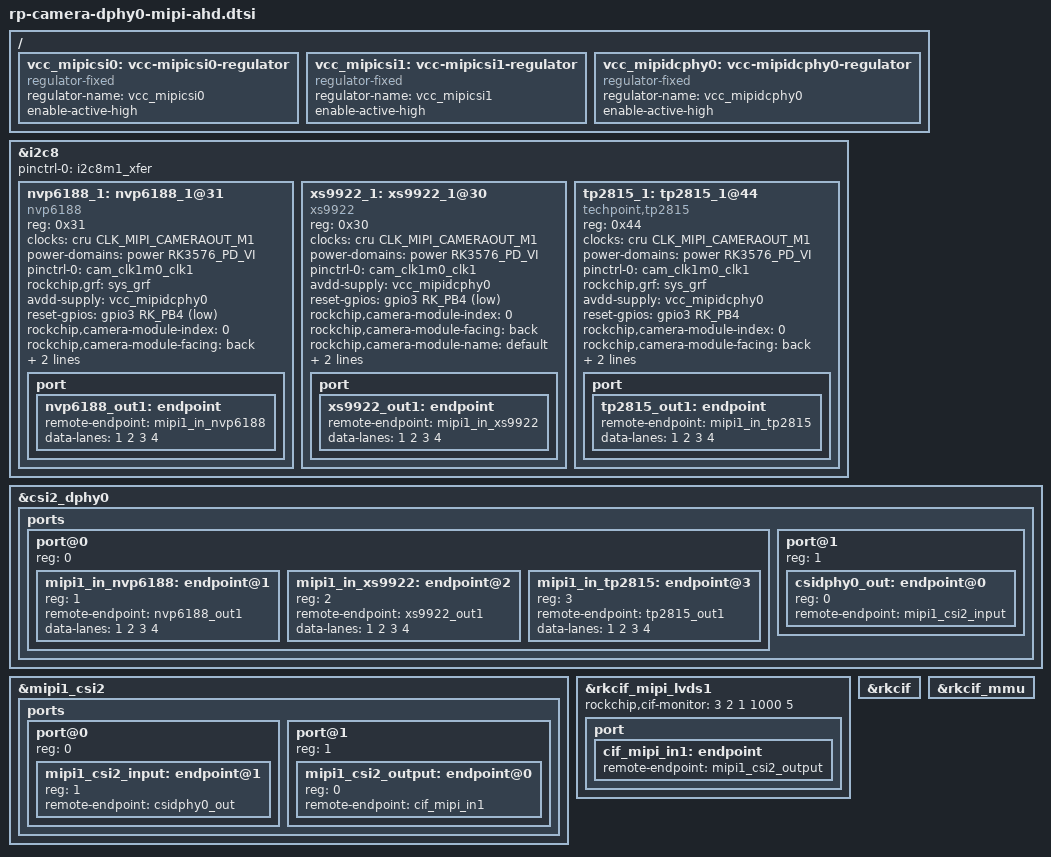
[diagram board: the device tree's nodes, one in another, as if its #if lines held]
/*
 * xs9922_0 -> MIPI_DPHY0 -> mipi_dcphy0 -> mipi0_csi2 -> cif0
 */

/{
    vcc_mipicsi0: vcc-mipicsi0-regulator {
        compatible = "regulator-fixed";
        regulator-name = "vcc_mipicsi0";
        enable-active-high;
    };

    vcc_mipicsi1: vcc-mipicsi1-regulator {
        compatible = "regulator-fixed";
        regulator-name = "vcc_mipicsi1";
        enable-active-high;
    };

    vcc_mipidcphy0: vcc-mipidcphy0-regulator {
        compatible = "regulator-fixed";
        regulator-name = "vcc_mipidcphy0";
        enable-active-high;
    };
};


&i2c8 {
    status = "okay";
    pinctrl-names = "default";
    pinctrl-0 = <&i2c8m1_xfer>;

    nvp6188_1: nvp6188_1@31 {
        reg = <0x31>;
        compatible = "nvp6188";
        status = "okay";
        clocks = <&cru CLK_MIPI_CAMERAOUT_M1>;
        clock-names = "xvclk";
        power-domains = <&power RK3576_PD_VI>;
        pinctrl-names = "default";
        pinctrl-0 = <&cam_clk1m0_clk1>;
		rockchip,grf = <&sys_grf>;
		avdd-supply = <&vcc_mipidcphy0>;
		
#if defined RP_RK3576S || defined PRO_RK3576X
        reset-gpios = <&gpio3 RK_PB4 GPIO_ACTIVE_LOW>;
        //power-gpios = <&nca9555_gpio IO_01 GPIO_ACTIVE_HIGH>;
#elif defined  DR4_RK3576X
        reset-gpios = <&gpio3 RK_PB4 GPIO_ACTIVE_LOW>;
        //power-gpios = <&nca9555_gpio IO_01 GPIO_ACTIVE_HIGH>;
#elif defined  PRO_RK3576_MID
        reset-gpios = <&gpio2 RK_PB0 GPIO_ACTIVE_LOW>;
        //power-gpios = <&nca9555_gpio IO_01 GPIO_ACTIVE_HIGH>;
#elif defined  PRO_BOX_RK3576
        reset-gpios = <&gpio0 RK_PA2 GPIO_ACTIVE_LOW>;
        //power-gpios = <&nca9555_gpio IO_01 GPIO_ACTIVE_HIGH>;
#else  //rk3576
        reset-gpios = <&nca9555_gpio IO_02 GPIO_ACTIVE_LOW>;
        //power-gpios = <&nca9555_gpio IO_03 GPIO_ACTIVE_HIGH>;
#endif        

        //avdd-supply = <&vcc_avdd>;
        //dovdd-supply = <&vcc_dovdd>;
        //dvdd-supply = <&vcc_dvdd>;
        rockchip,camera-module-index = <0>;
        rockchip,camera-module-facing = "back";
        rockchip,camera-module-name = "nvp6188";
        rockchip,camera-module-lens-name = "nvp6188";
        port {
            nvp6188_out1: endpoint {
                remote-endpoint = <&mipi1_in_nvp6188>;
                data-lanes = <1 2 3 4>;
            };
        };
    };
    
#ifdef PRO_RK3576_VIDEO
    xs9922_1: xs9922_1@30 {
        reg = <0x30>;
#else
    xs9922_1: xs9922_1@31 {
        reg = <0x31>;
#endif
        compatible = "xs9922";
        status = "okay";
        clocks = <&cru CLK_MIPI_CAMERAOUT_M1>;
        clock-names = "xvclk";
        power-domains = <&power RK3576_PD_VI>;
        pinctrl-names = "default";
        pinctrl-0 = <&cam_clk1m0_clk1>;
		avdd-supply = <&vcc_mipidcphy0>;
		
#if defined RP_RK3576S || defined PRO_RK3576X
        reset-gpios = <&gpio3 RK_PB4 GPIO_ACTIVE_LOW>;
        //power-gpios = <&nca9555_gpio IO_01 GPIO_ACTIVE_HIGH>;
#elif defined  DR4_RK3576X
        reset-gpios = <&gpio3 RK_PB4 GPIO_ACTIVE_LOW>;
        //power-gpios = <&nca9555_gpio IO_01 GPIO_ACTIVE_HIGH>;
#elif defined  PRO_RK3576_MID
        reset-gpios = <&gpio2 RK_PB0 GPIO_ACTIVE_LOW>;
        //power-gpios = <&nca9555_gpio IO_01 GPIO_ACTIVE_HIGH>;
#elif defined  PRO_BOX_RK3576
        reset-gpios = <&gpio0 RK_PA2 GPIO_ACTIVE_LOW>;
        //power-gpios = <&nca9555_gpio IO_01 GPIO_ACTIVE_HIGH>;
#else  //rk3576
        reset-gpios = <&nca9555_gpio IO_02 GPIO_ACTIVE_LOW>;
        //power-gpios = <&nca9555_gpio IO_03 GPIO_ACTIVE_HIGH>;
#endif        

        //avdd-supply = <&vcc_avdd>;
        //dovdd-supply = <&vcc_dovdd>;
        //dvdd-supply = <&vcc_dvdd>;
        rockchip,camera-module-index = <0>;
        rockchip,camera-module-facing = "back";
        rockchip,camera-module-name = "default";
        rockchip,camera-module-lens-name = "default";
        rockchip,default_rect= <1280 720>; 
        port {
            xs9922_out1: endpoint {
                remote-endpoint = <&mipi1_in_xs9922>;
                data-lanes = <1 2 3 4>;
            };
        };
    };
    
    
    tp2815_1: tp2815_1@44 {
        reg = <0x44>;
        compatible = "techpoint,tp2815";
        status = "okay";
        clocks = <&cru CLK_MIPI_CAMERAOUT_M1>;
        clock-names = "xvclk";
        power-domains = <&power RK3576_PD_VI>;
        pinctrl-names = "default";
        pinctrl-0 = <&cam_clk1m0_clk1>;
		rockchip,grf = <&sys_grf>;
		avdd-supply = <&vcc_mipidcphy0>;
		
#if defined RP_RK3576S || defined PRO_RK3576X
        reset-gpios = <&gpio3 RK_PB4 GPIO_ACTIVE_HIGH>;
        //power-gpios = <&nca9555_gpio IO_01 GPIO_ACTIVE_HIGH>;
#elif defined  DR4_RK3576X
        reset-gpios = <&gpio3 RK_PB4 GPIO_ACTIVE_HIGH>;
        //power-gpios = <&nca9555_gpio IO_01 GPIO_ACTIVE_HIGH>;
#elif defined  PRO_RK3576_MID
        reset-gpios = <&gpio2 RK_PB0 GPIO_ACTIVE_HIGH>;
        //power-gpios = <&nca9555_gpio IO_01 GPIO_ACTIVE_HIGH>;
#elif defined  PRO_BOX_RK3576
        reset-gpios = <&gpio0 RK_PA2 GPIO_ACTIVE_HIGH>;
        //power-gpios = <&nca9555_gpio IO_01 GPIO_ACTIVE_HIGH>;
#else  //rk3576
        reset-gpios = <&nca9555_gpio IO_02 GPIO_ACTIVE_HIGH>;
        //power-gpios = <&nca9555_gpio IO_03 GPIO_ACTIVE_HIGH>;
#endif        

        //avdd-supply = <&vcc_avdd>;
        //dovdd-supply = <&vcc_dovdd>;
        //dvdd-supply = <&vcc_dvdd>;
        rockchip,camera-module-index = <0>;
        rockchip,camera-module-facing = "back";
        rockchip,camera-module-name = "tp2815";
        rockchip,camera-module-lens-name = "tp2815";
        port {
            tp2815_out1: endpoint {
                remote-endpoint = <&mipi1_in_tp2815>;
                data-lanes = <1 2 3 4>;
            };
        };
    };
};
// CIF
&csi2_dphy0 {
    status = "okay";

    ports {
        #address-cells = <1>;
        #size-cells = <0>;
        port@0 {
            reg = <0>;
            #address-cells = <1>;
            #size-cells = <0>;

            mipi1_in_nvp6188: endpoint@1 {
                reg = <1>;
                remote-endpoint = <&nvp6188_out1>;
                data-lanes = <1 2 3 4>;
            };
	    
            mipi1_in_xs9922: endpoint@2 {
                reg = <2>;
                remote-endpoint = <&xs9922_out1>;
                data-lanes = <1 2 3 4>;
            };
	    
            mipi1_in_tp2815: endpoint@3 {
                reg = <3>;
                remote-endpoint = <&tp2815_out1>;
                data-lanes = <1 2 3 4>;
            };
        };
        port@1 {
            reg = <1>;
            #address-cells = <1>;
            #size-cells = <0>;

            csidphy0_out: endpoint@0 {
                reg = <0>;
                remote-endpoint = <&mipi1_csi2_input>;
            };
        };
    };
};


&mipi1_csi2 {
    status = "okay";

    ports {
        #address-cells = <1>;
        #size-cells = <0>;

        port@0 {
            reg = <0>;
            #address-cells = <1>;
            #size-cells = <0>;

            mipi1_csi2_input: endpoint@1 {
                reg = <1>;
                remote-endpoint = <&csidphy0_out>;
            };
        };

        port@1 {
            reg = <1>;
            #address-cells = <1>;
            #size-cells = <0>;

            mipi1_csi2_output: endpoint@0 {
                reg = <0>;
                remote-endpoint = <&cif_mipi_in1>;
            };
        };
    };
};

&rkcif_mipi_lvds1 {
    status = "okay";
    rockchip,cif-monitor = <3 2 1 1000 5>;
    port {
        cif_mipi_in1: endpoint {
            remote-endpoint = <&mipi1_csi2_output>;
        };
    };
};
&rkcif {
    status = "okay";
};

&rkcif_mmu {
    status = "okay";
};

#if 0
&rkcif_mipi_lvds1_sditf {
	status = "okay";

	port {
		mipi_lvds1_sditf: endpoint {
			remote-endpoint = <&isp_vir0_in1>;
		};
	};
};

&rkisp {
	status = "okay";
};

&rkisp_mmu {
	status = "okay";
};

&rkisp_vir0 {
	status = "okay";

	port {
		#address-cells = <1>;
		#size-cells = <0>;

		isp_vir0_in1: endpoint@0 {
			reg = <0>;
			remote-endpoint = <&mipi_lvds1_sditf>;
		};
	};
};
&rkisp_vir1_sditf {
    status = "okay";
};

&rkvpss {
    status = "okay";
};

&rkvpss_mmu {
    status = "okay";
};

&rkvpss_vir1 {
    status = "okay";
};

#endif

